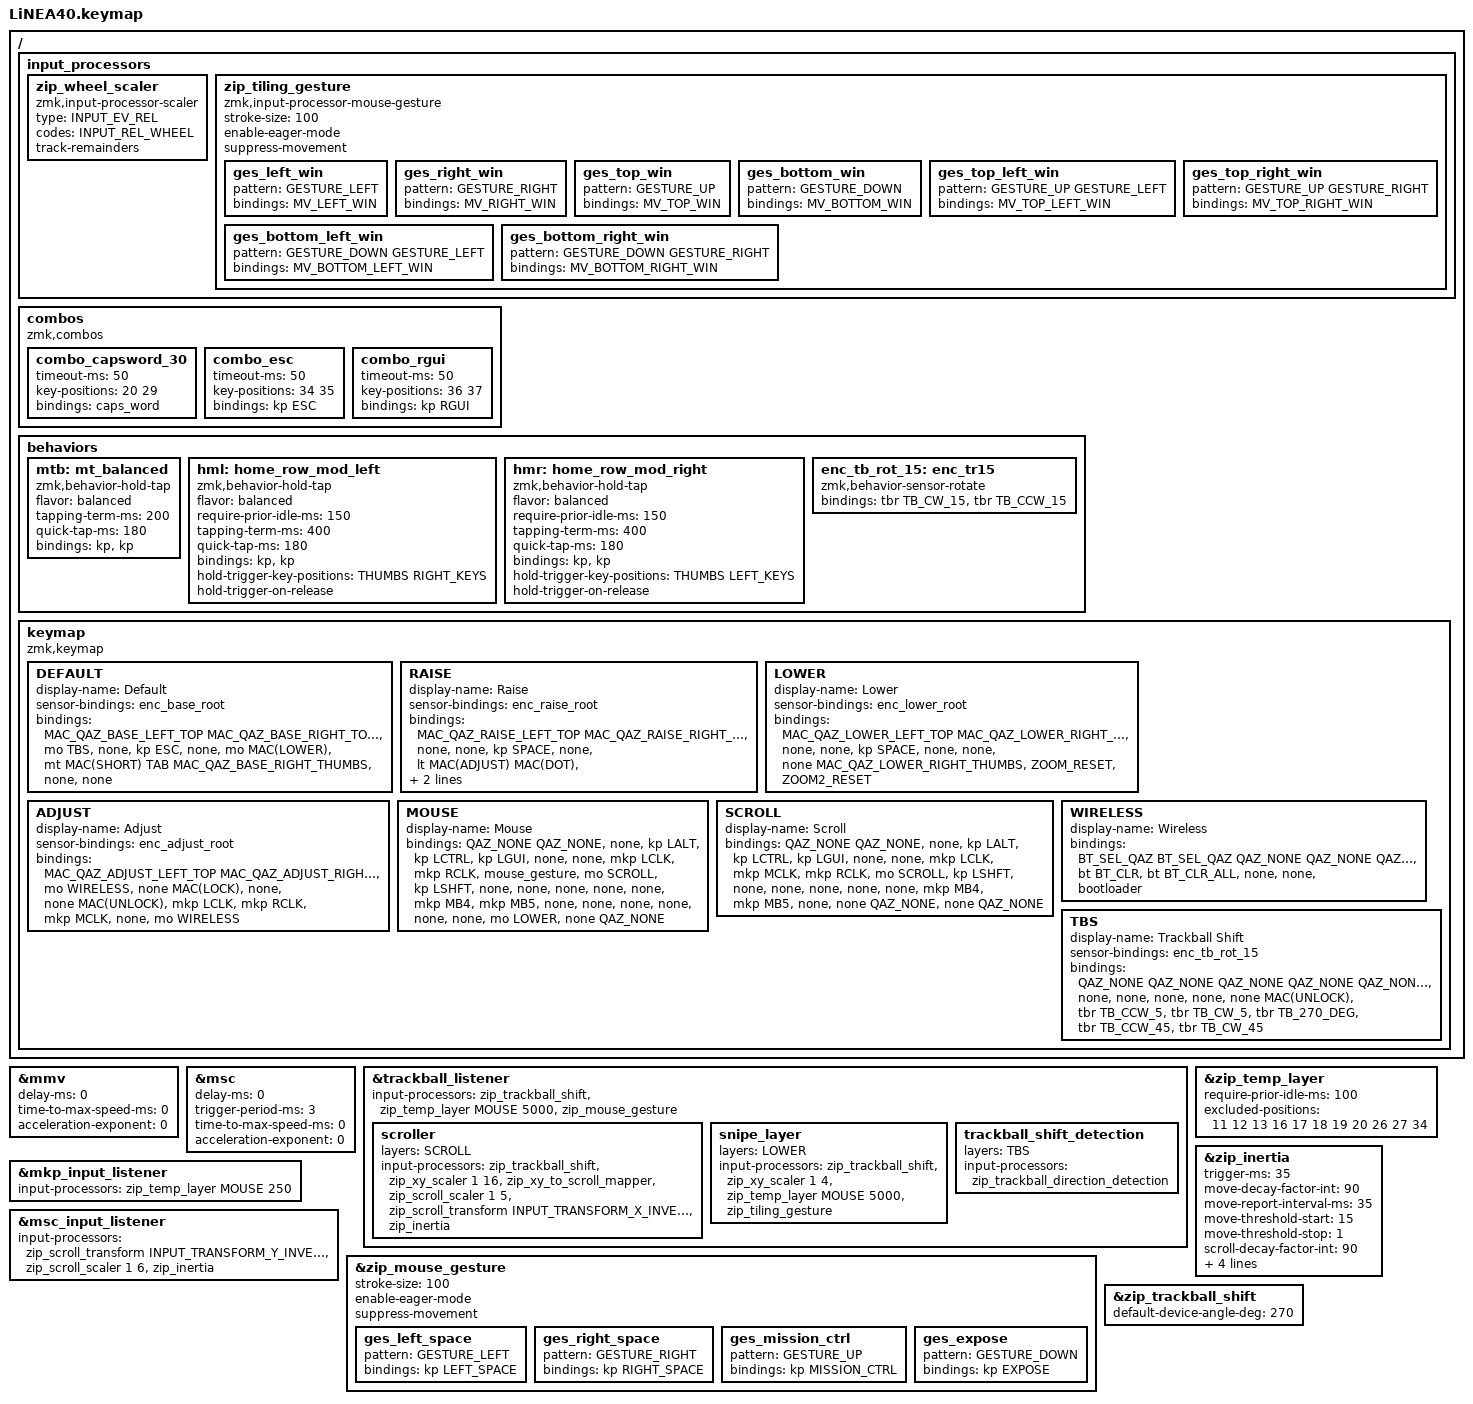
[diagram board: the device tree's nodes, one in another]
#define ZMK_POINTING_DEFAULT_MOVE_VAL 1500
#define ZMK_POINTING_DEFAULT_SCRL_VAL 50

#include <dt-bindings/zmk/input_transform.h>
#include <input/processors.dtsi>
#include <zephyr/dt-bindings/input/input-event-codes.h>
#include <behaviors.dtsi>
#include <dt-bindings/zmk/bt.h>
#include <dt-bindings/zmk/keys.h>
#include <dt-bindings/zmk/pointing.h>
#include <input_processors/trackball_shift.dtsi>
#include <input_processors/trackball_direction_detection.dtsi>
#include <behaviors/trackball_shift_rotation.dtsi>
#include <behaviors/trackball_direction_detection.dtsi>
#include <zmk-input-inertia/input/processor/input_inertia.dtsi>
#include <mouse-gesture.dtsi>
#include "us_keymap.h"
#include "us_encoder.h"

#define DEFAULT   0
#define RAISE     1
#define LOWER     2
#define ADJUST    3
#define MOUSE     4
#define SCROLL    5
#define WIRELESS  6
#define TBS  7

//╭───────┬───────┬───────┬───────┬───────╮                                   ╭───────┬───────┬───────┬───────┬───────╮
//|    0  |    1  |    2  |    3  |    4  |                                   |    5  |    6  |    7  |    8  |    9  |
//├───────┼───────┼───────┼───────┼───────┤                                   ├───────┼───────┼───────┼───────┼───────┤
//|   10  |   11  |   12  |   13  |   14  |                                   |   15  |   16  |   17  |   18  |   19  |
//├───────┼───────┼───────┼───────┼───────┤                                   ├───────┼───────┼───────┼───────┼───────┤
//|   20  |   21  |   22  |   23  |   24  |                                   |   25  |   26  |   27  |   28  |   29  |
//├───────┼───────┼───────┼───────┼───────┼───────╮                   ╭───────┼───────┼───────┼───────┼───────┼───────┤
//|   30  |   31  |   32  |   33  |   34  |   35  |                   |   36  |   37  |       |   38  |   39  |   40  |
//╰───────┴───────┴───────╯       ╰───────┴───────╯                   ╰───────┴───────╯       ╰───────┴───────┴───────╯

#define LEFT_TOP             0  1  2  3  4
#define RIGHT_TOP            5  6  7  8  9
#define LEFT_MID            10 11 12 13 14
#define RIGHT_MID           15 16 17 18 19
#define LEFT_BOTTOM         20 21 22 23 24
#define RIGHT_BOTTOM        25 26 27 28 29
#define LEFT_THUMBS         30 31 32 33 34 35
#define RIGHT_THUMBS        36 37 38 39 40

#define LEFT_KEYS  LEFT_TOP  LEFT_MID  LEFT_BOTTOM
#define RIGHT_KEYS RIGHT_TOP RIGHT_MID RIGHT_BOTTOM
#define THUMBS     LEFT_THUMBS RIGHT_THUMBS

#define BT_SEL_QAZ  &bt BT_SEL 0  &bt BT_SEL 1  &bt BT_SEL 2  &bt BT_SEL 3  &bt BT_SEL 4

#define LEFT_SPACE   LC(LEFT)
#define RIGHT_SPACE  LC(RIGHT)
#define MISSION_CTRL LC(UP)
#define EXPOSE       LC(DOWN)

#define MV_LEFT_WIN     kp LS(LG(LEFT))
#define MV_RIGHT_WIN    kp LS(LG(RIGHT))
#define MV_TOP_WIN      kp LS(LG(UP))
#define MV_BOTTOM_WIN   kp LS(LG(DOWN))

#define MV_TOP_LEFT_WIN      kp LG(LA(LEFT))
#define MV_TOP_RIGHT_WIN     kp LG(LA(UP))
#define MV_BOTTOM_LEFT_WIN   kp LG(LA(DOWN))
#define MV_BOTTOM_RIGHT_WIN  kp LG(LA(RIGHT))

//mouse cursol

&mmv {
    delay-ms = <0>;
    time-to-max-speed-ms = <0>;
    acceleration-exponent = <0>;
};

//mouse scroll

&msc {
    delay-ms = <0>; // default: 0. LiNEA40 default: 3.
    trigger-period-ms = <3>; // default: 16. LiNEA40 default: 3
    time-to-max-speed-ms = <0>; //default: 0. LiNEA40 default: 100
    acceleration-exponent = <0>;
};

/ {
    input_processors {
        zip_wheel_scaler: zip_wheel_scaler {
            compatible = "zmk,input-processor-scaler";
            #input-processor-cells = <2>;
            type = <INPUT_EV_REL>;
            codes = <INPUT_REL_WHEEL>;
            track-remainders;
        };

        zip_tiling_gesture: zip_tiling_gesture {
            compatible = "zmk,input-processor-mouse-gesture";
            #input-processor-cells = <0>;

            stroke-size = <100>; // default: 200
            enable-eager-mode;
            suppress-movement;

            ges_left_win {
                pattern = <GESTURE_LEFT>;
                bindings = <&MV_LEFT_WIN>;
            };

            ges_right_win {
                pattern = <GESTURE_RIGHT>;
                bindings = <&MV_RIGHT_WIN>;
            };

            ges_top_win {
                pattern = <GESTURE_UP>;
                bindings = <&MV_TOP_WIN>;
            };

            ges_bottom_win {
                pattern = <GESTURE_DOWN>;
                bindings = <&MV_BOTTOM_WIN>;
            };

            ges_top_left_win {
                pattern = <GESTURE_UP GESTURE_LEFT>;
                bindings = <&MV_TOP_LEFT_WIN>;
            };

            ges_top_right_win {
                pattern = <GESTURE_UP GESTURE_RIGHT>;
                bindings = <&MV_TOP_RIGHT_WIN>;
            };

            ges_bottom_left_win {
                pattern = <GESTURE_DOWN GESTURE_LEFT>;
                bindings = <&MV_BOTTOM_LEFT_WIN>;
            };

            ges_bottom_right_win {
                pattern = <GESTURE_DOWN GESTURE_RIGHT>;
                bindings = <&MV_BOTTOM_RIGHT_WIN>;
            };
        };
    };
};

&trackball_listener {
    input-processors = <
            &zip_trackball_shift
            &zip_temp_layer MOUSE 5000
            &zip_mouse_gesture
    >;

    scroller {
        layers = <SCROLL>;
        input-processors = <
            &zip_trackball_shift
            &zip_xy_scaler 1 16
            &zip_xy_to_scroll_mapper &zip_scroll_scaler 1 5
            &zip_scroll_transform INPUT_TRANSFORM_X_INVERT
            &zip_inertia
        >;
    };

    snipe_layer {
        layers = <LOWER>;
        input-processors = <
            &zip_trackball_shift
            &zip_xy_scaler 1 4
            &zip_temp_layer MOUSE 5000
            &zip_tiling_gesture
        >;
    };

    trackball_shift_detection {
        layers = <TBS>;
        input-processors = <&zip_trackball_direction_detection>;
    };
};

&zip_temp_layer {
    require-prior-idle-ms = <100>;
    excluded-positions = <
           11 12 13               16 17 18 19
        20                        26 27
                 34
    >;
};

&mkp_input_listener {
    input-processors = <&zip_temp_layer MOUSE 250>;
};

&msc_input_listener {
    input-processors = <
        &zip_scroll_transform INPUT_TRANSFORM_Y_INVERT
        &zip_scroll_scaler 1 6
        &zip_inertia
    >;
};

&zip_inertia {
    // 慣性が始まるまでの待ち時間 (推奨: センサーのポーリングレートの2倍以上)
    trigger-ms = <35>; 

    // --- マウス移動の設定 ---
    move-decay-factor-int = <90>;       // 減衰率 (0-100)
    move-report-interval-ms = <35>;     // レポート送信間隔 (ms)
    move-threshold-start = <15>;        // 慣性が発動する最小移動量 (pix/report)
    move-threshold-stop = <1>;          // 慣性が停止する移動量 (pix/report)

    // --- スクロールの設定 ---
    scroll-decay-factor-int = <90>;    // スクロール減衰率
    scroll-report-interval-ms = <65>;  // スクロールレポート間隔 (ms)
    scroll-threshold-start = <1>;      // 慣性が発動する最小スクロール量 (pix/report)
    scroll-threshold-stop = <0>;       // 慣性が停止するスクロール量 (pix/report)

    cancel-scroll-inertia-on-ctrl;
};

&zip_mouse_gesture {
    stroke-size = <100>; // default: 200
    enable-eager-mode;
    suppress-movement;

    ges_left_space {
        pattern = <GESTURE_LEFT>;
        bindings = <&kp LEFT_SPACE>;
    };

    ges_right_space {
        pattern = <GESTURE_RIGHT>;
        bindings = <&kp RIGHT_SPACE>;
    };

    ges_mission_ctrl {
        pattern = <GESTURE_UP>;
        bindings = <&kp MISSION_CTRL>;
    };

    ges_expose {
        pattern = <GESTURE_DOWN>;
        bindings = <&kp EXPOSE>;
    };
};

&zip_trackball_shift {
    default-device-angle-deg = <270>;
};

/ {
    combos {
        compatible = "zmk,combos";

        // left and right shift for 30% keyboard layout
        combo_capsword_30 {
            timeout-ms = <50>;
            key-positions = <20 29>;
            bindings = <&caps_word>;
        };

        // left thumbs
        combo_esc {
            timeout-ms = <50>;
            key-positions = <34 35>;
            bindings = <&kp ESC>;
        };

        // right thumbs
        combo_rgui {
            timeout-ms = <50>;
            key-positions = <36 37>;
            bindings = <&kp RGUI>;
        };
    };

    behaviors {
        mtb: mt_balanced {
            compatible = "zmk,behavior-hold-tap";
            #binding-cells = <2>;
            flavor = "balanced";
            tapping-term-ms = <200>;
            quick-tap-ms = <180>;
            bindings = <&kp>, <&kp>;
        };

        hml: home_row_mod_left {
            compatible = "zmk,behavior-hold-tap";
            #binding-cells = <2>;
            flavor = "balanced";
            require-prior-idle-ms = <150>;
            tapping-term-ms = <400>;
            quick-tap-ms = <180>;
            bindings = <&kp>, <&kp>;
            hold-trigger-key-positions = <THUMBS RIGHT_KEYS>;
            hold-trigger-on-release;
        };

        hmr: home_row_mod_right {
            compatible = "zmk,behavior-hold-tap";
            #binding-cells = <2>;
            flavor = "balanced";
            require-prior-idle-ms = <150>;
            tapping-term-ms = <400>;
            quick-tap-ms = <180>;
            bindings = <&kp>, <&kp>;
            hold-trigger-key-positions = <THUMBS LEFT_KEYS>;
            hold-trigger-on-release;
        };

        enc_tb_rot_15: enc_tr15 {
            compatible = "zmk,behavior-sensor-rotate";
            #sensor-binding-cells = <0>;
            bindings = <&tbr TB_CW_15>, <&tbr TB_CCW_15>;
        };
    };

    keymap {
        compatible = "zmk,keymap";

        DEFAULT {
            display-name = "Default";
            sensor-bindings = <&enc_base_root>;
            bindings = <
                MAC_QAZ_BASE_LEFT_TOP                                                 MAC_QAZ_BASE_RIGHT_TOP
                MAC_QAZ_BASE_LEFT_MIDDLE                                              MAC_QAZ_BASE_RIGHT_MIDDLE
                MAC_QAZ_BASE_LEFT_BOTTOM                                              MAC_QAZ_BASE_RIGHT_BOTTOM
                &mo TBS  &none  &kp ESC  &none  &mo MAC(LOWER)  &mt MAC(SHORT) TAB    MAC_QAZ_BASE_RIGHT_THUMBS  &none  &none
            >;
        };

        RAISE {
            display-name = "Raise";
            sensor-bindings = <&enc_raise_root>;
            bindings = <
                MAC_QAZ_RAISE_LEFT_TOP                                                           MAC_QAZ_RAISE_RIGHT_TOP
                MAC_QAZ_RAISE_LEFT_MIDDLE                                                        MAC_QAZ_RAISE_RIGHT_MIDDLE
                MAC_QAZ_RAISE_LEFT_BOTTOM                                                        MAC_QAZ_RAISE_RIGHT_BOTTOM
                &none  &none  &kp SPACE  &none  &lt MAC(ADJUST) MAC(DOT)  &mt MAC(SHORT) BSPC    MAC_QAZ_RAISE_RIGHT_THUMBS  &none  &none
            >;
        };

        LOWER {
            display-name = "Lower";
            sensor-bindings = <&enc_lower_root>;
            bindings = <
                MAC_QAZ_LOWER_LEFT_TOP                          MAC_QAZ_LOWER_RIGHT_TOP
                MAC_QAZ_LOWER_LEFT_MIDDLE                       MAC_QAZ_LOWER_RIGHT_MIDDLE
                MAC_QAZ_LOWER_LEFT_BOTTOM                       MAC_QAZ_LOWER_RIGHT_BOTTOM
                &none  &none  &kp SPACE  &none  &none  &none    MAC_QAZ_LOWER_RIGHT_THUMBS  &ZOOM_RESET  &ZOOM2_RESET
            >;
        };

        ADJUST {
            display-name = "Adjust";
            sensor-bindings = <&enc_adjust_root>;
            bindings = <
                MAC_QAZ_ADJUST_LEFT_TOP                                      MAC_QAZ_ADJUST_RIGHT_TOP
                MAC_QAZ_ADJUST_LEFT_MIDDLE                                   MAC_QAZ_ADJUST_RIGHT_MIDDLE
                MAC_QAZ_ADJUST_LEFT_BOTTOM                                   MAC_QAZ_ADJUST_RIGHT_BOTTOM
                &mo WIRELESS  &none  MAC(LOCK)  &none  &none  MAC(UNLOCK)    &mkp LCLK  &mkp RCLK  &mkp MCLK  &none  &mo WIRELESS
            >;
        };

        MOUSE {
            display-name = "Mouse";
            bindings = <
                QAZ_NONE                                                      QAZ_NONE
                &none      &kp LALT  &kp LCTRL  &kp LGUI  &none               &none  &mkp LCLK  &mkp RCLK  &mouse_gesture  &mo SCROLL
                &kp LSHFT  &none     &none      &none     &none               &none  &mkp MB4   &mkp MB5   &none      &none
                &none      &none     &none      &none     &mo LOWER  &none    QAZ_NONE
            >;
        };

        SCROLL {
            display-name = "Scroll";
            bindings = <
                QAZ_NONE                                                      QAZ_NONE
                &none      &kp LALT  &kp LCTRL  &kp LGUI  &none               &none  &mkp LCLK  &mkp MCLK  &mkp RCLK  &mo SCROLL
                &kp LSHFT  &none     &none      &none     &none               &none  &mkp MB4   &mkp MB5   &none      &none
                QAZ_NONE   &none                                              QAZ_NONE
            >;
        };

        WIRELESS {
            display-name = "Wireless";
            bindings = <
                BT_SEL_QAZ               BT_SEL_QAZ
                QAZ_NONE                 QAZ_NONE
                QAZ_NONE                 QAZ_NONE
                QAZ_NONE  MAC(UNLOCK)    &bt BT_CLR  &bt BT_CLR_ALL  &none  &none  &bootloader
            >;
        };

        TBS {
            display-name = "Trackball Shift";
            sensor-bindings = <&enc_tb_rot_15>;
            bindings = <
                QAZ_NONE                                           QAZ_NONE
                QAZ_NONE                                           QAZ_NONE
                QAZ_NONE                                           QAZ_NONE
                &none  &none  &none  &none  &none  MAC(UNLOCK)     &tbr TB_CCW_5  &tbr TB_CW_5  &tbr TB_270_DEG  &tbr TB_CCW_45  &tbr TB_CW_45
            >;
        };
    };
};
